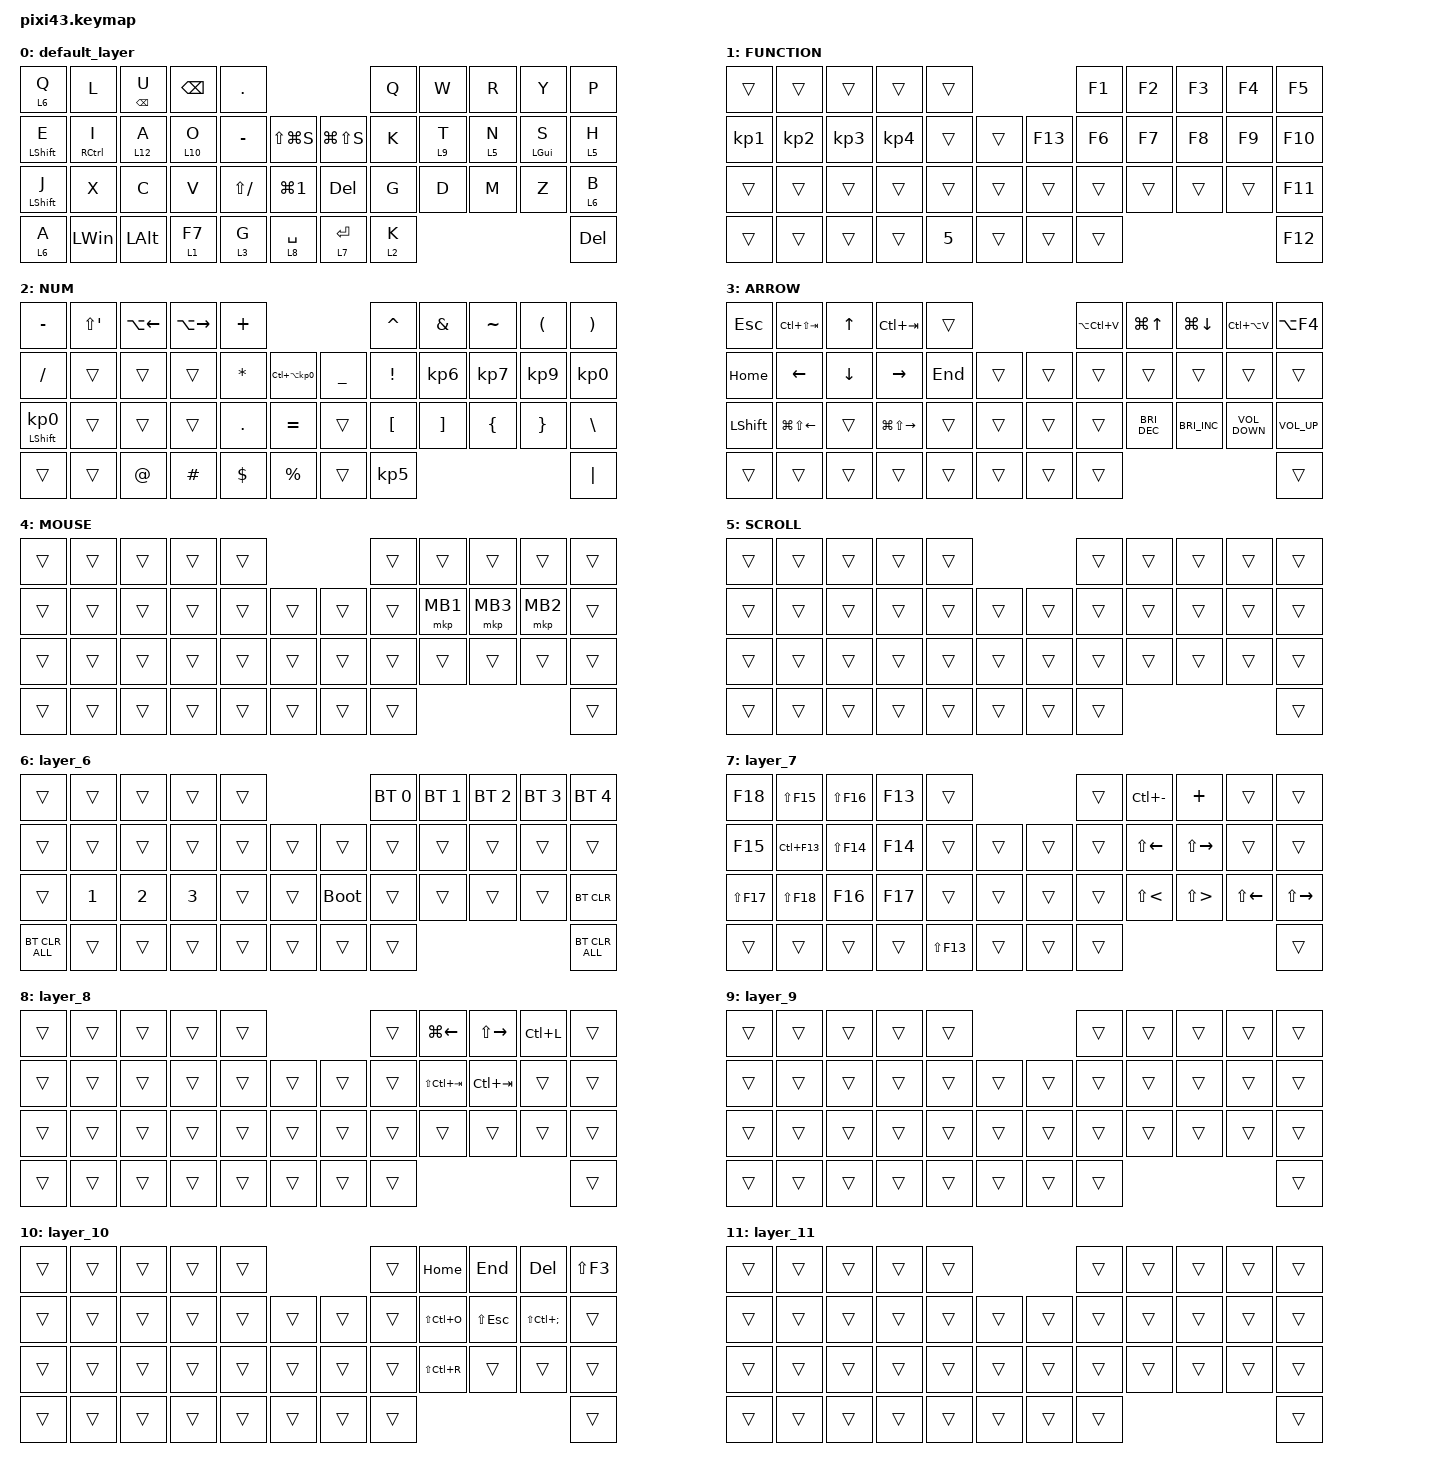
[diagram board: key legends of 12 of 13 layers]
#include <behaviors.dtsi>
#include <dt-bindings/zmk/bt.h>
#include <dt-bindings/zmk/keys.h>
#include <dt-bindings/zmk/pointing.h>

&mt {
    flavor = "balanced";
    quick-tap-ms = <0>;
};

&trackball {
    automouse-layer = <4>;
    scroll-layers = <5>;

    // arrows {
    //     layers = <3>;
    //     bindings =
    //         <&kp RIGHT_ARROW>,
    //         <&kp LEFT_ARROW>,
    //         <&kp UP_ARROW>,
    //         <&kp DOWN_ARROW>;
    //     tick = <10>;
    //     wait-ms = <5>;
    //     tap-ms = <5>;
    // };
};

/ {
    combos {
        compatible = "zmk,combos";

        tab {
            bindings = <&kp TAB>;
            key-positions = <11 12 38>;
        };

        shift_tab {
            bindings = <&kp LS(TAB)>;
            key-positions = <12 13 38>;
        };

        muhennkann {
            bindings = <&to_layer_0 INT_MUHENKAN>;
            key-positions = <11 10>;
        };

        double_quotation {
            bindings = <&kp DOUBLE_QUOTES>;
            key-positions = <20 21>;
        };

        eq {
            bindings = <&kp EQUAL>;
            key-positions = <24 25>;
        };

        ActivePrtScr {
            bindings = <&kp LA(PRINTSCREEN)>;
            key-positions = <32 31>;
            timeout-ms = <40>;
            require-prior-idle-ms = <0>;
            layers = <0>;
            slow-release;
        };

        Paste {
            bindings = <&kp LC(V)>;
            key-positions = <31 30>;
            timeout-ms = <40>;
            slow-release;
            layers = <0>;
        };

        Windows_Voice_Input {
            bindings = <&kp LG(H)>;
            key-positions = <12 13>;
            timeout-ms = <40>;
            slow-release;
            layers = <0>;
        };

        WordDelete {
            bindings = <&kp LC(BACKSPACE)>;
            key-positions = <2 3>;
            timeout-ms = <40>;
            slow-release;
            layers = <0>;
        };

        English {
            bindings = <&kp LANG2>;
            key-positions = <13 38>;
            timeout-ms = <40>;
            slow-release;
            layers = <0>;
        };

        copy {
            bindings = <&kp V>;
            key-positions = <12 38>;
            timeout-ms = <40>;
            slow-release;
            layers = <0>;
        };

        SelectAll {
            bindings = <&kp LC(A)>;
            key-positions = <10 11>;
            slow-release;
            timeout-ms = <40>;
        };

        Cut {
            bindings = <&kp LC(X)>;
            key-positions = <11 38>;
            timeout-ms = <40>;
            slow-release;
            layers = <0>;
        };

        Search {
            bindings = <&kp LC(F)>;
            key-positions = <6 41>;
            timeout-ms = <40>;
            slow-release;
            layers = <0>;
        };

        Undo {
            bindings = <&kp LC(Z)>;
            key-positions = <41 19>;
            layers = <0>;
            timeout-ms = <40>;
        };

        Redo {
            bindings = <&kp LC(Y)>;
            key-positions = <41 20>;
            timeout-ms = <40>;
            slow-release;
            layers = <0>;
        };

        SelectLeft {
            bindings = <&kp LS(LEFT)>;
            key-positions = <34 35>;
            timeout-ms = <40>;
            slow-release;
            layers = <0>;
        };

        SelectRight {
            bindings = <&kp LS(RIGHT)>;
            key-positions = <35 36>;
            timeout-ms = <40>;
            slow-release;
            layers = <0>;
        };

        CreateNewVirtualDesktop {
            bindings = <&kp LC(LG(D))>;
            key-positions = <41 8>;
            timeout-ms = <40>;
            slow-release;
            layers = <0>;
        };

        CloseCurrentVirtualDesktop {
            bindings = <&kp LG(LC(F4))>;
            key-positions = <41 9>;
            timeout-ms = <40>;
            slow-release;
            layers = <0>;
        };

        SwitchToTheDesktopOnTheRight {
            bindings = <&kp LG(LC(RIGHT))>;
            key-positions = <9 8>;
            timeout-ms = <40>;
            slow-release;
            layers = <0>;
        };

        SwitchToTheDesktopOnTheLeft {
            bindings = <&kp LC(LG(LEFT))>;
            key-positions = <8 7>;
        };

        MaximizeWindow {
            bindings = <&kp LG(UP)>;
            key-positions = <38 25>;
            timeout-ms = <40>;
            slow-release;
            layers = <0>;
        };

        MinimizeWindow {
            bindings = <&kp LG(DOWN)>;
            key-positions = <38 22>;
            timeout-ms = <40>;
            slow-release;
            layers = <0>;
        };

        SnapWindowLeft {
            bindings = <&kp LG(LEFT)>;
            key-positions = <38 23>;
            timeout-ms = <40>;
            slow-release;
            layers = <0>;
        };

        SnapWindowRight {
            bindings = <&kp LG(RIGHT)>;
            key-positions = <38 24>;
            timeout-ms = <40>;
            slow-release;
            layers = <0>;
        };

        SwitchActiveWindowRight {
            bindings = <&kp RA(TAB)>;
            key-positions = <41 21>;
            timeout-ms = <40>;
            slow-release;
            layers = <0>;
        };

        MoveWindowToRightMonitor {
            bindings = <&kp LS(LG(RIGHT))>;
            key-positions = <14 38>;
        };

        CloseApplication {
            bindings = <&kp LA(F4)>;
            key-positions = <38 11>;
        };

        SwitchActiveWindowLeft {
            bindings = <&kp LA(TAB)>;
            key-positions = <10 38>;
            timeout-ms = <40>;
        };

        japanese {
            bindings = <&kp LANGUAGE_1>;
            key-positions = <18 41>;
        };
    };

    macros {
        to_layer_0: to_layer_0 {
            compatible = "zmk,behavior-macro-one-param";
            #binding-cells = <1>;
            bindings = <&to 0 &macro_param_1to1 &kp MACRO_PLACEHOLDER>;
            label = "TO_LAYER_0";
        };

        takahito: takahito {
            compatible = "zmk,behavior-macro";
            #binding-cells = <0>;
            bindings = <&kp T &kp A &kp K &kp A &kp H &kp I &kp T &kp O &kp SPACE &kp ENTER>;
            label = "TAKAHITO";
        };

        nn: nn {
            compatible = "zmk,behavior-macro";
            #binding-cells = <0>;
            bindings = <&none>;
            label = "NN";
        };
    };

    behaviors {
        lt_to_layer_0: lt_to_layer_0 {
            compatible = "zmk,behavior-hold-tap";
            label = "LAYER_TAP_TO_0";
            bindings = <&mo>, <&to_layer_0>;

            #binding-cells = <2>;
            tapping-term-ms = <200>;
        };
    };

    keymap {
        compatible = "zmk,keymap";

        default_layer {
            bindings = <
&lt_to_layer_0 6 Q  &kp L         &mt BACKSPACE U      &kp BACKSPACE        &kp PERIOD                                                         &kp Q    &kp W               &kp R               &kp Y           &kp P
&mt LEFT_SHIFT E    &mt RCTRL I   &lt_to_layer_0 12 A  &lt_to_layer_0 10 O  &kp MINUS      &kp LS(LG(S))               &kp LG(LS(S))           &kp K    &lt_to_layer_0 9 T  &lt_to_layer_0 5 N  &mt LEFT_GUI S  &lt_to_layer_0 5 H
&mt LEFT_SHIFT J    &kp X         &kp C                &kp V                &kp LS(SLASH)  &kp LG(N1)                  &kp DELETE              &kp G    &kp D               &kp M               &kp Z           &lt_to_layer_0 6 B
&lt_to_layer_0 6 A  &kp LEFT_WIN  &kp LEFT_ALT         &lt_to_layer_0 1 F7  &lt 3 G        &lt_to_layer_0 8 SPACE      &lt_to_layer_0 7 ENTER  &lt 2 K                                                          &kp DEL
            >;

            sensor-bindings = <&inc_dec_kp PG_UP PAGE_DOWN>;
        };

        FUNCTION {
            bindings = <
&trans           &trans           &trans           &trans           &trans                             &kp F1  &kp F2  &kp F3  &kp F4  &kp F5
&kp KP_NUMBER_1  &kp KP_NUMBER_2  &kp KP_NUMBER_3  &kp KP_NUMBER_4  &trans        &trans      &kp F13  &kp F6  &kp F7  &kp F8  &kp F9  &kp F10
&trans           &trans           &trans           &trans           &trans        &trans      &trans   &trans  &trans  &trans  &trans  &kp F11
&trans           &trans           &trans           &trans           &kp NUMBER_5  &trans      &trans   &trans                          &kp F12
            >;
        };

        NUM {
            bindings = <
&kp MINUS                   &kp LS(SINGLE_QUOTE)  &kp LA(LEFT)  &kp LA(RIGHT)  &kp PLUS                                                   &kp CARET         &kp AMPERSAND      &kp TILDE        &kp LEFT_PARENTHESIS  &kp RIGHT_PARENTHESIS
&kp SLASH                   &trans                &trans        &trans         &kp ASTERISK  &kp LC(LA(KP_NUMBER_0))      &kp UNDERSCORE  &kp EXCLAMATION   &kp KP_NUMBER_6    &kp KP_NUMBER_7  &kp KP_NUMBER_9       &kp KP_NUMBER_0
&mt LEFT_SHIFT KP_NUMBER_0  &trans                &trans        &trans         &kp PERIOD    &kp EQUAL                    &trans          &kp LEFT_BRACKET  &kp RIGHT_BRACKET  &kp LEFT_BRACE   &kp RIGHT_BRACE       &kp BACKSLASH
&trans                      &trans                &kp AT        &kp HASH       &kp DOLLAR    &kp PERCENT                  &trans          &kp KP_NUMBER_5                                                             &kp PIPE
            >;
        };

        ARROW {
            bindings = <
&kp ESCAPE      &kp LC(LS(TAB))         &kp UP_ARROW    &kp LC(TAB)              &trans                       &kp LA(LC(V))  &kp LG(UP)            &kp LG(DOWN)          &kp LC(LA(V))      &kp LA(F4)
&kp HOME        &kp LEFT_ARROW          &kp DOWN_ARROW  &kp RIGHT_ARROW          &kp END  &trans      &trans  &trans         &trans                &trans                &trans             &trans
&kp LEFT_SHIFT  &kp LG(LS(LEFT_ARROW))  &trans          &kp LG(LS(RIGHT_ARROW))  &trans   &trans      &trans  &trans         &kp C_BRIGHTNESS_DEC  &kp C_BRIGHTNESS_INC  &kp C_VOLUME_DOWN  &kp C_VOLUME_UP
&trans          &trans                  &trans          &trans                   &trans   &trans      &trans  &trans                                                                        &trans
            >;

            sensor-bindings = <&inc_dec_kp LC(PAGE_UP) LC(PAGE_DOWN)>;
        };

        MOUSE {
            bindings = <
&trans  &trans  &trans  &trans  &trans                      &trans  &trans    &trans    &trans    &trans
&trans  &trans  &trans  &trans  &trans  &trans      &trans  &trans  &mkp MB1  &mkp MB3  &mkp MB2  &trans
&trans  &trans  &trans  &trans  &trans  &trans      &trans  &trans  &trans    &trans    &trans    &trans
&trans  &trans  &trans  &trans  &trans  &trans      &trans  &trans                                &trans
            >;
        };

        SCROLL {
            bindings = <
&trans  &trans  &trans  &trans  &trans                      &trans  &trans  &trans  &trans  &trans
&trans  &trans  &trans  &trans  &trans  &trans      &trans  &trans  &trans  &trans  &trans  &trans
&trans  &trans  &trans  &trans  &trans  &trans      &trans  &trans  &trans  &trans  &trans  &trans
&trans  &trans  &trans  &trans  &trans  &trans      &trans  &trans                          &trans
            >;
        };

        layer_6 {
            bindings = <
&trans          &trans        &trans        &trans        &trans                           &bt BT_SEL 0  &bt BT_SEL 1  &bt BT_SEL 2  &bt BT_SEL 3  &bt BT_SEL 4
&trans          &trans        &trans        &trans        &trans  &trans      &trans       &trans        &trans        &trans        &trans        &trans
&trans          &kp NUMBER_1  &kp NUMBER_2  &kp NUMBER_3  &trans  &trans      &bootloader  &trans        &trans        &trans        &trans        &bt BT_CLR
&bt BT_CLR_ALL  &trans        &trans        &trans        &trans  &trans      &trans       &trans                                                  &bt BT_CLR_ALL
            >;
        };

        layer_7 {
            bindings = <
&kp F18      &kp LS(F15)  &kp LS(F16)  &kp F13  &trans                           &trans  &kp LC(MINUS)      &kp PLUS              &trans        &trans
&kp F15      &kp LC(F13)  &kp LS(F14)  &kp F14  &trans       &trans      &trans  &trans  &kp LS(LEFT)       &kp LS(RIGHT)         &trans        &trans
&kp LS(F17)  &kp LS(F18)  &kp F16      &kp F17  &trans       &trans      &trans  &trans  &kp LS(LESS_THAN)  &kp LS(GREATER_THAN)  &kp LS(LEFT)  &kp LS(RIGHT)
&trans       &trans       &trans       &trans   &kp LS(F13)  &trans      &trans  &trans                                                         &trans
            >;
        };

        layer_8 {
            bindings = <
&trans  &trans  &trans  &trans  &trans                      &trans  &kp LG(LEFT)     &kp LS(RIGHT)  &kp LC(L)  &trans
&trans  &trans  &trans  &trans  &trans  &trans      &trans  &trans  &kp LS(LC(TAB))  &kp LC(TAB)    &trans     &trans
&trans  &trans  &trans  &trans  &trans  &trans      &trans  &trans  &trans           &trans         &trans     &trans
&trans  &trans  &trans  &trans  &trans  &trans      &trans  &trans                                             &trans
            >;
        };

        layer_9 {
            bindings = <
&trans  &trans  &trans  &trans  &trans                      &trans  &trans  &trans  &trans  &trans
&trans  &trans  &trans  &trans  &trans  &trans      &trans  &trans  &trans  &trans  &trans  &trans
&trans  &trans  &trans  &trans  &trans  &trans      &trans  &trans  &trans  &trans  &trans  &trans
&trans  &trans  &trans  &trans  &trans  &trans      &trans  &trans                          &trans
            >;
        };

        layer_10 {
            bindings = <
&trans  &trans  &trans  &trans  &trans                      &trans  &kp HOME       &kp END         &kp DELETE             &kp LS(F3)
&trans  &trans  &trans  &trans  &trans  &trans      &trans  &trans  &kp LS(LC(O))  &kp LS(ESCAPE)  &kp LS(LC(SEMICOLON))  &trans
&trans  &trans  &trans  &trans  &trans  &trans      &trans  &trans  &kp LS(LC(R))  &trans          &trans                 &trans
&trans  &trans  &trans  &trans  &trans  &trans      &trans  &trans                                                        &trans
            >;
        };

        layer_11 {
            bindings = <
&trans  &trans  &trans  &trans  &trans                      &trans  &trans  &trans  &trans  &trans
&trans  &trans  &trans  &trans  &trans  &trans      &trans  &trans  &trans  &trans  &trans  &trans
&trans  &trans  &trans  &trans  &trans  &trans      &trans  &trans  &trans  &trans  &trans  &trans
&trans  &trans  &trans  &trans  &trans  &trans      &trans  &trans                          &trans
            >;
        };

        layer_12 {
            bindings = <
&trans  &trans  &trans  &trans  &trans                      &trans  &trans  &trans  &trans  &trans
&trans  &trans  &trans  &trans  &trans  &trans      &trans  &trans  &trans  &trans  &trans  &trans
&trans  &trans  &trans  &trans  &trans  &trans      &trans  &trans  &trans  &trans  &trans  &trans
&trans  &trans  &trans  &trans  &trans  &trans      &trans  &trans                          &trans
            >;
        };
    };
};
